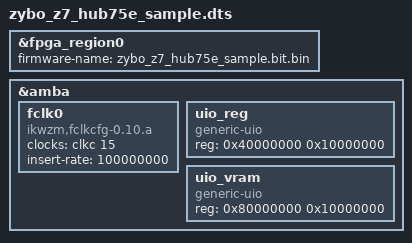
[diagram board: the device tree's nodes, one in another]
/dts-v1/; /plugin/;

/ {
    fragment@0 {  
        target = <&fpga_region0>;
        __overlay__ {
            #address-cells = <1>;
            #size-cells = <1>;

            firmware-name = "zybo_z7_hub75e_sample.bit.bin";
        };
    };

    fragment@1 {
        target = <&amba>;
        __overlay__ {
            fclk0 {
                compatible  = "ikwzm,fclkcfg-0.10.a";
                clocks      = <&clkc 15>;
                insert-rate = "100000000";
            };
        };
    };

    fragment@2 {
        target = <&amba>;
        __overlay__ {
            #address-cells = <0x1>;
            #size-cells = <0x1>;
            
            uio_reg {
                compatible = "generic-uio";
                reg = <0x40000000 0x10000000>;
            };
            uio_vram {
                compatible = "generic-uio";
                reg = <0x80000000 0x10000000>;
            };
        };
    };
};


